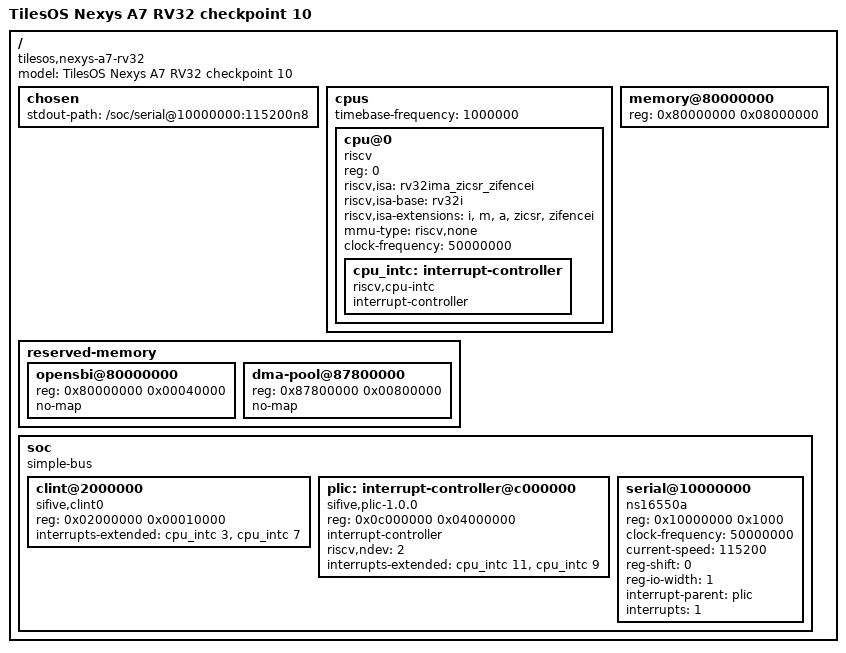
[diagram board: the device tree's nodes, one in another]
/dts-v1/;
/ {
    #address-cells = <1>;
    #size-cells = <1>;
    model = "TilesOS Nexys A7 RV32 checkpoint 10";
    compatible = "tilesos,nexys-a7-rv32";
    chosen { stdout-path = "/soc/serial@10000000:115200n8"; };
    cpus {
        #address-cells = <1>;
        #size-cells = <0>;
        timebase-frequency = <1000000>;
        cpu@0 {
            device_type = "cpu";
            reg = <0>;
            status = "okay";
            compatible = "riscv";
            riscv,isa = "rv32ima_zicsr_zifencei";
            riscv,isa-base = "rv32i";
            riscv,isa-extensions = "i", "m", "a", "zicsr", "zifencei";
            // Bare-only at checkpoint 10; Sv32 is introduced at checkpoint 11.
            mmu-type = "riscv,none";
            clock-frequency = <50000000>;
            cpu_intc: interrupt-controller {
                compatible = "riscv,cpu-intc";
                interrupt-controller;
                #interrupt-cells = <1>;
            };
        };
    };
    memory@80000000 {
        device_type = "memory";
        reg = <0x80000000 0x08000000>;
    };
    reserved-memory {
        #address-cells = <1>;
        #size-cells = <1>;
        ranges;
        opensbi@80000000 { reg = <0x80000000 0x00040000>; no-map; };
        dma-pool@87800000 { reg = <0x87800000 0x00800000>; no-map; };
    };
    soc {
        #address-cells = <1>;
        #size-cells = <1>;
        compatible = "simple-bus";
        ranges;
        clint@2000000 {
            compatible = "sifive,clint0", "riscv,clint0";
            reg = <0x02000000 0x00010000>;
            interrupts-extended = <&cpu_intc 3 &cpu_intc 7>;
        };
        plic: interrupt-controller@c000000 {
            compatible = "sifive,plic-1.0.0", "riscv,plic0";
            reg = <0x0c000000 0x04000000>;
            interrupt-controller;
            #interrupt-cells = <1>;
            #address-cells = <0>;
            riscv,ndev = <2>;
            interrupts-extended = <&cpu_intc 11 &cpu_intc 9>;
        };
        serial@10000000 {
            compatible = "ns16550a";
            reg = <0x10000000 0x1000>;
            clock-frequency = <50000000>;
            current-speed = <115200>;
            reg-shift = <0>;
            reg-io-width = <1>;
            interrupt-parent = <&plic>;
            interrupts = <1>;
        };
    };
};
